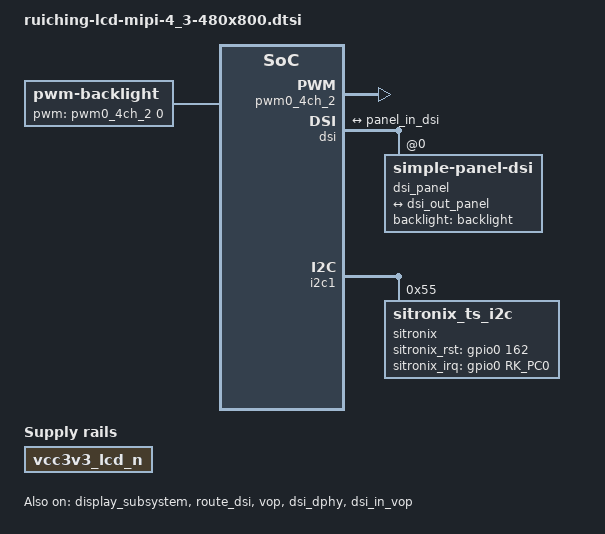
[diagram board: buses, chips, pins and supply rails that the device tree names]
/{
    backlight: backlight {
        compatible = "pwm-backlight";
        pwms = <&pwm0_4ch_2 0 25000 0>;
        brightness-levels = <
              0  20  20  21  21  22  22  23
             23  24  24  25  25  26  26  27
             27  28  28  29  29  30  30  31
             31  32  32  33  33  34  34  35
             35  36  36  37  37  38  38  39
             40  41  42  43  44  45  46  47
             48  49  50  51  52  53  54  55
             56  57  58  59  60  61  62  63
             64  65  66  67  68  69  70  71
             72  73  74  75  76  77  78  79
             80  81  82  83  84  85  86  87
             88  89  90  91  92  93  94  95
             96  97  98  99 100 101 102 103
            104 105 106 107 108 109 110 111
            112 113 114 115 116 117 118 119
            120 121 122 123 124 125 126 127
            128 129 130 131 132 133 134 135
            136 137 138 139 140 141 142 143
            144 145 146 147 148 149 150 151
            152 153 154 155 156 157 158 159
            160 161 162 163 164 165 166 167
            168 169 170 171 172 173 174 175
            176 177 178 179 180 181 182 183
            184 185 186 187 188 189 190 191
            192 193 194 195 196 197 198 199
            200 201 202 203 204 205 206 207
            208 209 210 211 212 213 214 215
            216 217 218 219 220 221 222 223
            224 225 226 227 228 229 230 231
            232 233 234 235 236 237 238 239
            240 241 242 243 244 245 246 247
            248 249 250 251 252 253 254 255
        >;
        default-brightness-level = <200>;
    };

    vcc3v3_lcd_n: vcc3v3-lcd0-n {
        compatible = "regulator-fixed";
        enable-active-high;
        //gpio = <&gpio4 RK_PB3 GPIO_ACTIVE_HIGH>;
        regulator-name = "vcc3v3_lcd_n";
        regulator-boot-on;
        regulator-state-mem {
            regulator-off-in-suspend;
        };
    };
};

&pwm0_4ch_2 {
    status = "okay";
};

&display_subsystem {
    status = "okay";
    logo-memory-region = <&drm_logo>;
};

&dsi {
    status = "okay";
    // rockchip,lane-rate = <450>;
    dsi_panel: panel@0 {
        status = "okay";
        compatible = "simple-panel-dsi";
        reg = <0>;
        backlight = <&backlight>;
        prepare-delay-ms = <20>;
        reset-delay-ms = <80>;
        init-delay-ms = <240>;
        disable-delay-ms = <10>;
        unprepare-delay-ms = <5>;
        width-mm = <154>;
        height-mm = <85>;

        dsi,flags = <(MIPI_DSI_MODE_VIDEO | MIPI_DSI_MODE_VIDEO_BURST |
                    MIPI_DSI_MODE_LPM | MIPI_DSI_MODE_NO_EOT_PACKET)>;
        dsi,format = <MIPI_DSI_FMT_RGB888>;
        dsi,lanes  = <2>;
        panel-init-sequence = [
        //        00 01 02 03 04 05 06 07 08 09 10 11 12 13 14 15 16 17 18 19 20 21 22 23 24 25 26 27 28 29 30 31 32 33 34 35 36 37 38 39 40 41 42 43 44 45 46 47 48 49 50
        //		  00 01 02 03 04 05 06 07 08 09 0a 0b 0c 0d 0e 0f 10 11 12 13 14 15 16 17 18 19 1a 1b 1c 1d 1e 1f 20 21 22 23 24 25 26 27 28 29 2a 2b 2c 2d 2e 2f 30 31 32
            29 00 04 99 71 02 a2
            29 00 04 99 71 02 a3
            29 00 04 99 71 02 a4
            15 00 02 a4 31
            39 00 08 b0 22 57 1e 61 2f 57 61
            39 00 03 b7 64 64
            39 00 03 bf b4 b4
            29 00 26 C8 00 00 0F 1C 34 00 60 03 A0 06 10 FE 06 74 03 21 C4 00 08 00 22 46 0F 8F 0A 32 F2 0C 42 0C F3 80 00 AB C0 03 C4
            29 00 26 C9 00 00 0F 1C 34 00 60 03 A0 06 10 FE 06 74 03 21 C4 00 08 00 22 46 0F 8F 0A 32 F2 0C 42 0C F3 80 00 AB C0 03 C4
            39 00 07 d7 10 0c 36 19 90 90
            39 00 21 A3 51 03 80 CF 44 00 00 00 00 04 78 78 00 1A 00 45 05 00 00 00 00 46 00 00 02 20 52 00 05 00 00 FF
        	39 00 2d A6 02 00 24 55 35 00 38 00 78 78 00 24 55 36 00 37 00 78 78 02 AC 51 3A 00 00 00 78 78 03 AC 21 00 04 00 00 78 78 3e 00 06 00 00 00 00
        	39 00 31 A7 19 19 00 64 40 07 16 40 00 04 03 78 78 00 64 40 25 34 00 00 02 01 78 78 00 64 40 4B 5A 00 00 02 01 78 78 00 24 40 69 78 00 00 00 00 78 78 00 44
        	39 00 26 AC 08 0A 11 00 13 03 1B 18 06 1A 19 1B 1B 1B 18 1B 09 0B 10 02 12 01 1B 18 06 1A 19 1B 1B 1B 18 1B FF 67 FF 67 00
        	39 00 08 ad cc 40 46 11 04 78 78
        	39 00 0f e8 30 07 00 94 94 9c 00 e2 04 00 00 00 00 ef
        	39 00 22 E7 8B 3C 00 0C F0 5D 00 5D 00 5D 00 5D 00 FF 00 08 7B 00 00 C8 6A 5A 08 1A 3C 00 81 01 CC 01 7F F0 22
        	05 14 01 11
        	05 14 01 29
        	15 00 02 35 00
        ];

        disp_timings0: display-timings {
            native-mode = <&dsi_timing0>;
            dsi_timing0: timing0 {
                clock-frequency = <33300000>;
                hactive = <480>;
                vactive = <800>;
                hback-porch = <40>;
                hfront-porch = <40>;
                vback-porch = <10>;
                vfront-porch = <180>;
                hsync-len = <2>;
                vsync-len = <2>;
                hsync-active = <0>;
                vsync-active = <0>;
                de-active = <0>;
                pixelclk-active = <0>;
            };
        };

        ports {
            #address-cells = <1>;
            #size-cells = <0>;
            port@0 {
                reg = <0>;
                panel_in_dsi: endpoint {
                    remote-endpoint = <&dsi_out_panel>;
                };
            };
        };
    };

    ports {
        #address-cells = <1>;
        #size-cells = <0>;
        port@1 {
            reg = <1>;
            dsi_out_panel: endpoint {
                remote-endpoint = <&panel_in_dsi>;
            };
        };
    };
};

&route_dsi {
    status = "okay";
};

&vop {
    status = "okay";
};

&cma {
    size = <0x1600000>;
};

&dsi_dphy {
        status = "okay";
};

&dsi_in_vop {
        status = "okay";
};

&i2c1 {
    status = "okay";
    pinctrl-names = "default";

    sitronix@55 {
        status = "okay";
        compatible = "sitronix_ts_i2c";
        reg = <0x55>;
        resolution_x = <480>;
        resolution_y = <800>;

        sitronix_rst_gpio = <&gpio0 162 GPIO_ACTIVE_HIGH>;
        sitronix_irq_gpio = <&gpio0 RK_PC0 IRQ_TYPE_EDGE_FALLING>;
    };
};
